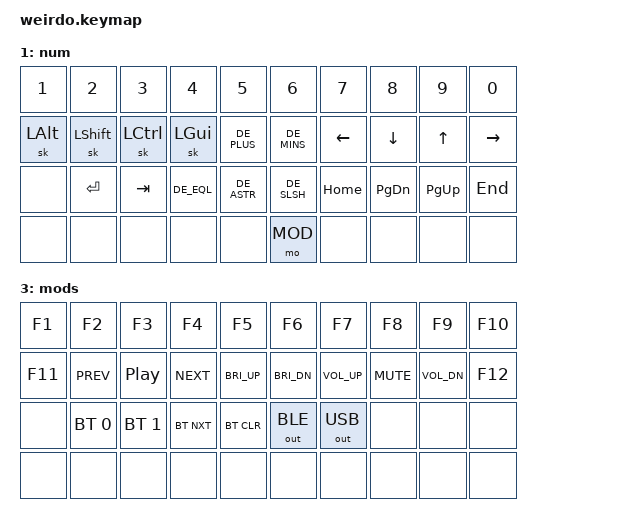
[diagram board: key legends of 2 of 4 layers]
/*
 * Copyright (c) 2021 The ZMK Contributors
 *
 * SPDX-License-Identifier: MIT
 */

#include <behaviors.dtsi>
#include <dt-bindings/zmk/keys.h>
#include <dt-bindings/zmk/bt.h>
#include <dt-bindings/zmk/outputs.h>

/* GERMAN KEY CODES */
#define DE_CIRC GRAVE // ^ (dead)
#define DE_SS   MINUS // ß
#define DE_ACUT EQUAL // ´ (dead)
#define DE_Q    Q            // Q
#define DE_W    W            // W
#define DE_E    E            // E
#define DE_R    R            // R
#define DE_T    T            // T
#define DE_Z    Y            // Z
#define DE_U    U            // U
#define DE_I    I            // I
#define DE_O    O            // O
#define DE_P    P            // P
#define DE_UDIA LEFT_BRACKET // Ü
#define DE_PLUS RIGHT_BRACKET // +
#define DE_A    A            // A
#define DE_S    S            // S
#define DE_D    D            // D
#define DE_F    F            // F
#define DE_G    G            // G
#define DE_H    H            // H
#define DE_J    J            // J
#define DE_K    K            // K
#define DE_L    L            // L
#define DE_ODIA SEMICOLON    // Ö
#define DE_ADIA SINGLE_QUOTE // Ä
#define DE_HASH NON_US_HASH  // #
#define DE_LABK NON_US_BACKSLASH // <
#define DE_Y    Z                // Y
#define DE_X    X                // X
#define DE_C    C                // C
#define DE_V    V                // V
#define DE_B    B                // B
#define DE_N    N                // N
#define DE_M    M                // M
#define DE_COMM COMMA            // ,
#define DE_DOT  PERIOD           // .
#define DE_MINS SLASH            // -
#define DE_DEG  LS(DE_CIRC) // °
#define DE_EXLM LS(NUMBER_1)    // !
#define DE_DQUO LS(NUMBER_2)    // "
#define DE_SECT LS(NUMBER_3)    // §
#define DE_DLR  LS(NUMBER_4)    // $
#define DE_PERC LS(NUMBER_5)    // %
#define DE_AMPR LS(NUMBER_6)    // &
#define DE_SLSH LS(NUMBER_7)    // /
#define DE_LPRN LS(NUMBER_8)    // (
#define DE_RPRN LS(NUMBER_9)    // )
#define DE_EQL  LS(NUMBER_0)    // =
#define DE_QUES LS(DE_SS)   // ?
#define DE_GRV  LS(DE_ACUT) // ` (dead)
#define DE_ASTR LS(DE_PLUS) // *
#define DE_QUOT LS(DE_HASH) // '
#define DE_RABK LS(DE_LABK) // >
#define DE_SCLN LS(DE_COMM) // ;
#define DE_COLN LS(DE_DOT)  // :
#define DE_UNDS LS(DE_MINS) // _
#define DE_LBRC LA(NUMBER_5)    // [
#define DE_RBRC LA(NUMBER_6)    // ]
#define DE_PIPE LA(NUMBER_7)    // |
#define DE_LCBR LA(NUMBER_8)    // {
#define DE_RCBR LA(NUMBER_9)    // }
#define DE_AT LA(DE_L)    // @
#define DE_EURO LA(DE_E)    // €
#define DE_TILD LA(DE_N)    // ~
#define DE_BSLS LS(LA(NUMBER_7))    // (backslash)
                                     
#define _____ &none

&sk {
  quick-release;
};

#define ALP 0
#define NUM 1
#define SYM 2
#define MOD 3

#define DE_UE DE_UDIA
#define DE_AE DE_ADIA
#define DE_OE DE_ODIA

/ {
  keymap {
    compatible = "zmk,keymap";

    alpha_1 {
      bindings = <
        &kp ESCAPE  &kp DE_L  &kp DE_U  &kp DE_A  &kp DE_J                    &kp DE_W  &kp DE_B  &kp DE_D    &kp DE_G    &kp BACKSPACE
        &kp DE_C    &kp DE_R  &kp DE_I  &kp DE_E  &kp DE_O                    &kp DE_M  &kp DE_N  &kp DE_T    &kp DE_S    &kp DE_H
        &kp DE_V    &kp DE_X  &kp DE_Z  &kp DE_Y  &kp DE_Q                    &kp DE_P  &kp DE_F  &kp DE_COMM &kp DE_DOT  &kp DE_K  
        &kp LC(TAB) &kp DE_UE &kp DE_AE &sl NUM   &mt LC(LG(LS(LALT))) SPACE  &sk LSHFT &sl SYM   &kp DE_OE   &kp DE_SS   &kp LC(LS(TAB)) 
      >;
    };

    num {
      bindings = <
        &kp N1    &kp N2    &kp N3    &kp N4      &kp N5      &kp N6      &kp N7    &kp N8    &kp N9    &kp N0
        &sk LALT  &sk LSHFT &sk LCTRL &sk LGUI    &kp DE_PLUS &kp DE_MINS &kp LEFT  &kp DOWN  &kp UP    &kp RIGHT 
        _____     &kp ENTER &kp TAB   &kp DE_EQL  &kp DE_ASTR &kp DE_SLSH &kp HOME  &kp PG_DN &kp PG_UP &kp END 
        _____     _____     _____     _____       _____       &mo MOD     _____     _____     _____     _____
      >;
    };

    sym {
      bindings = <
        &kp DE_EURO &kp DE_UNDS &kp DE_LBRC &kp DE_RBRC &kp DE_CIRC           &kp DE_EXLM &kp DE_LABK &kp DE_RABK &kp DE_COLN &kp DE_AMPR  
        &kp DE_BSLS &kp DE_LPRN &kp DE_LCBR &kp DE_RCBR &kp DE_RPRN           &kp DE_QUES &sk LGUI    &sk LCTRL   &sk LSHFT   &sk LALT
        &kp DE_HASH &kp DE_DLR  &kp DE_PIPE &kp DE_TILD &kp DE_GRV            &kp DE_AT   &kp DE_PERC &kp DE_DQUO &kp DE_QUOT &kp DE_SCLN   
        _____       _____       _____       _____        _____       _____       _____       _____       _____
      >;
    };

    mods {
      bindings = <
        &kp F1  &kp F2        &kp F3            &kp F4      &kp F5        &kp F6        &kp F7        &kp F8      &kp F9        &kp F10
        &kp F11 &kp C_PREV    &kp C_PLAY_PAUSE  &kp C_NEXT  &kp C_BRI_UP  &kp C_BRI_DN  &kp C_VOL_UP  &kp C_MUTE  &kp C_VOL_DN  &kp F12
        _____   &bt BT_SEL 0  &bt BT_SEL 1      &bt BT_NXT  &bt BT_CLR    &out OUT_BLE  &out OUT_USB  _____       _____         _____ 
        _____   _____         _____             _____       _____         _____         _____         _____       _____         _____
      >;
    };

  };
};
